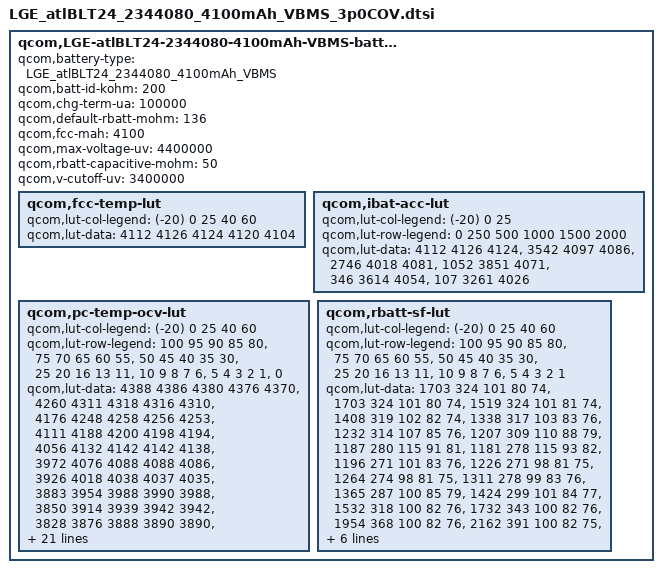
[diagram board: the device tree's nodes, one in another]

qcom,LGE-atlBLT24-2344080-4100mAh-VBMS-batterydata {
	qcom,battery-type = "LGE_atlBLT24_2344080_4100mAh_VBMS";
	qcom,batt-id-kohm = <200>;
	qcom,chg-term-ua = <100000>;
	qcom,default-rbatt-mohm = <136>;
	qcom,fcc-mah = <4100>;
	qcom,max-voltage-uv = <4400000>;
	qcom,rbatt-capacitive-mohm = <50>;
	qcom,v-cutoff-uv = <3400000>;

	qcom,fcc-temp-lut {
		qcom,lut-col-legend = <(-20) 0 25 40 60>;
		qcom,lut-data = <4112 4126 4124 4120 4104>;
	};

	qcom,ibat-acc-lut {
		qcom,lut-col-legend = <(-20) 0 25>;
		qcom,lut-row-legend = <0 250 500 1000 1500 2000>;
		qcom,lut-data = <4112 4126 4124>,
				<3542 4097 4086>,
				<2746 4018 4081>,
				<1052 3851 4071>,
				<346 3614 4054>,
				<107 3261 4026>;
	};

	qcom,pc-temp-ocv-lut {
		qcom,lut-col-legend = <(-20) 0 25 40 60>;
		qcom,lut-row-legend = <100 95 90 85 80>,
					<75 70 65 60 55>,
					<50 45 40 35 30>,
					<25 20 16 13 11>,
					<10 9 8 7 6>,
					<5 4 3 2 1>,
					<0>;
		qcom,lut-data = <4388 4386 4380 4376 4370>,
				<4260 4311 4318 4316 4310>,
				<4176 4248 4258 4256 4253>,
				<4111 4188 4200 4198 4194>,
				<4056 4132 4142 4142 4138>,
				<3972 4076 4088 4088 4086>,
				<3926 4018 4038 4037 4035>,
				<3883 3954 3988 3990 3988>,
				<3850 3914 3939 3942 3942>,
				<3828 3876 3888 3890 3890>,
				<3812 3845 3855 3856 3856>,
				<3796 3818 3829 3830 3830>,
				<3782 3798 3808 3808 3808>,
				<3768 3784 3790 3790 3790>,
				<3752 3772 3773 3772 3768>,
				<3734 3758 3756 3750 3738>,
				<3714 3738 3738 3729 3716>,
				<3696 3718 3717 3708 3695>,
				<3678 3702 3696 3688 3677>,
				<3664 3692 3689 3682 3670>,
				<3656 3688 3687 3680 3669>,
				<3647 3685 3686 3679 3668>,
				<3634 3680 3684 3677 3666>,
				<3620 3674 3680 3674 3662>,
				<3601 3664 3673 3666 3651>,
				<3576 3641 3651 3642 3622>,
				<3542 3600 3608 3597 3576>,
				<3494 3540 3548 3538 3516>,
				<3419 3455 3466 3456 3434>,
				<3282 3314 3336 3326 3305>,
				<3000 3000 3000 3000 3000>;
	};

	qcom,rbatt-sf-lut {
		qcom,lut-col-legend = <(-20) 0 25 40 60>;
		qcom,lut-row-legend = <100 95 90 85 80>,
					<75 70 65 60 55>,
					<50 45 40 35 30>,
					<25 20 16 13 11>,
					<10 9 8 7 6>,
					<5 4 3 2 1>;
		qcom,lut-data = <1703 324 101 80 74>,
				<1703 324 101 80 74>,
				<1519 324 101 81 74>,
				<1408 319 102 82 74>,
				<1338 317 103 83 76>,
				<1232 314 107 85 76>,
				<1207 309 110 88 79>,
				<1187 280 115 91 81>,
				<1181 278 115 93 82>,
				<1196 271 101 83 76>,
				<1226 271 98 81 75>,
				<1264 274 98 81 75>,
				<1311 278 99 83 76>,
				<1365 287 100 85 79>,
				<1424 299 101 84 77>,
				<1532 318 100 82 76>,
				<1732 343 100 82 76>,
				<1954 368 100 82 76>,
				<2162 391 100 82 75>,
				<2289 402 101 82 75>,
				<2385 408 101 82 76>,
				<2450 421 101 83 76>,
				<2662 438 104 85 78>,
				<2922 460 107 87 80>,
				<3260 486 110 88 79>,
				<3681 507 107 85 76>,
				<4259 537 106 84 77>,
				<5147 588 108 86 79>,
				<6582 668 113 88 80>,
				<11750 1029 130 105 99>;
	};
};
